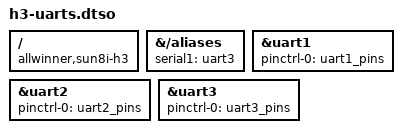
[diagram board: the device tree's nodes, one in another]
/dts-v1/;
/plugin/;

/ {
	compatible = "allwinner,sun8i-h3";

	fragment@0 {
		target-path = "/aliases";
		__overlay__ {
			serial1 =  <&uart1>;
		};
	};
	fragment@1 {
		target = <&uart1>;
		 __overlay__ {
			pinctrl-names = "default";
			pinctrl-0 = <&uart1_pins>;
			status = "okay";
		};
	};
	fragment@2 {
		target-path = "/aliases";
		__overlay__ {
			serial1 =  <&uart2>;
		};
	};
	fragment@3 {
		target = <&uart2>;
		 __overlay__ {
			pinctrl-names = "default";
			pinctrl-0 = <&uart2_pins>;
			status = "okay";
		};
	};
	fragment@4 {
		target-path = "/aliases";
		__overlay__ {
			serial1 =  <&uart3>;
		};
	};
	fragment@5 {
		target = <&uart3>;
		 __overlay__ {
			pinctrl-names = "default";
			pinctrl-0 = <&uart3_pins>;
			status = "okay";
		};
	};
};
